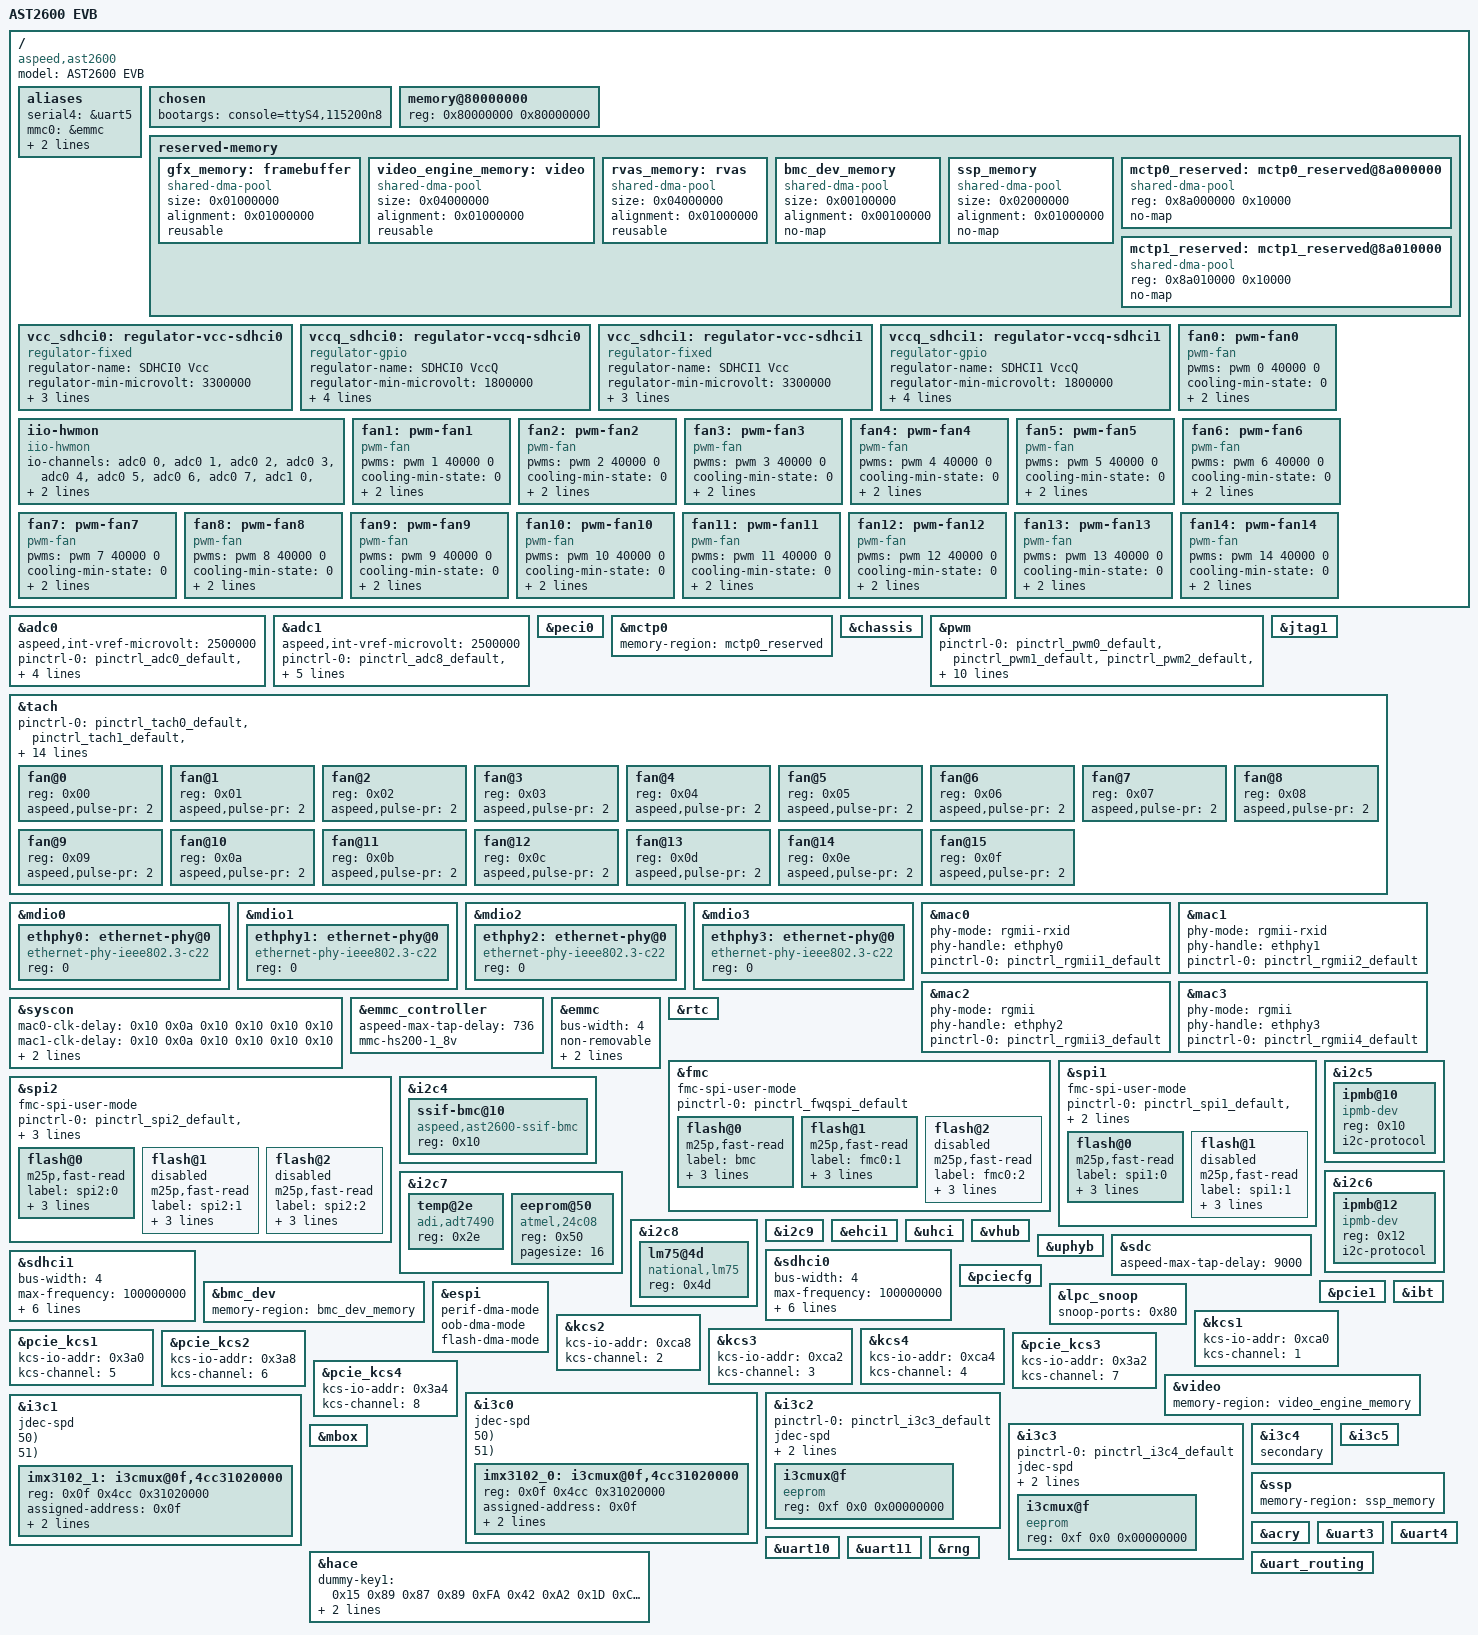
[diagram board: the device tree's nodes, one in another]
// SPDX-License-Identifier: GPL-2.0-or-later
// Copyright 2019 IBM Corp.

/dts-v1/;

#include "aspeed-g6.dtsi"
#include <dt-bindings/gpio/aspeed-gpio.h>

/ {
	model = "AST2600 EVB";
	compatible = "aspeed,ast2600";

	aliases {
		serial4 = &uart5;
		mmc0 = &emmc;
		mmc1 = &sdhci0;
		mmc2 = &sdhci1;
	};

	chosen {
		bootargs = "console=ttyS4,115200n8";
	};

	memory@80000000 {
		device_type = "memory";
		reg = <0x80000000 0x80000000>;
	};

	reserved-memory {
		#address-cells = <1>;
		#size-cells = <1>;
		ranges;

		gfx_memory: framebuffer {
			size = <0x01000000>;
			alignment = <0x01000000>;
			compatible = "shared-dma-pool";
			reusable;
		};

		video_engine_memory: video {
			size = <0x04000000>;
			alignment = <0x01000000>;
			compatible = "shared-dma-pool";
			reusable;
		};

		rvas_memory: rvas {
			size = <0x04000000>;
			alignment = <0x01000000>;
			compatible = "shared-dma-pool";
			reusable;
		};

		bmc_dev_memory: bmc_dev_memory {
			size = <0x00100000>;
			alignment = <0x00100000>;
			compatible = "shared-dma-pool";
			no-map;
		};

		ssp_memory: ssp_memory {
			size = <0x02000000>;
			alignment = <0x01000000>;
			compatible = "shared-dma-pool";
			no-map;
		};

		mctp0_reserved: mctp0_reserved@8a000000 {
			reg = <0x8a000000 0x10000>;
			compatible = "shared-dma-pool";
			no-map;
		};

		mctp1_reserved: mctp1_reserved@8a010000 {
			reg = <0x8a010000 0x10000>;
			compatible = "shared-dma-pool";
			no-map;
		};
	};

	vcc_sdhci0: regulator-vcc-sdhci0 {
		compatible = "regulator-fixed";
		regulator-name = "SDHCI0 Vcc";
		regulator-min-microvolt = <3300000>;
		regulator-max-microvolt = <3300000>;
		gpios = <&gpio0 ASPEED_GPIO(V, 0) GPIO_ACTIVE_HIGH>;
		enable-active-high;
	};

	vccq_sdhci0: regulator-vccq-sdhci0 {
		compatible = "regulator-gpio";
		regulator-name = "SDHCI0 VccQ";
		regulator-min-microvolt = <1800000>;
		regulator-max-microvolt = <3300000>;
		gpios = <&gpio0 ASPEED_GPIO(V, 1) GPIO_ACTIVE_HIGH>;
		gpios-states = <1>;
		states = <3300000 1>,
			 <1800000 0>;
	};

	vcc_sdhci1: regulator-vcc-sdhci1 {
		compatible = "regulator-fixed";
		regulator-name = "SDHCI1 Vcc";
		regulator-min-microvolt = <3300000>;
		regulator-max-microvolt = <3300000>;
		gpios = <&gpio0 ASPEED_GPIO(V, 2) GPIO_ACTIVE_HIGH>;
		enable-active-high;
	};

	vccq_sdhci1: regulator-vccq-sdhci1 {
		compatible = "regulator-gpio";
		regulator-name = "SDHCI1 VccQ";
		regulator-min-microvolt = <1800000>;
		regulator-max-microvolt = <3300000>;
		gpios = <&gpio0 ASPEED_GPIO(V, 3) GPIO_ACTIVE_HIGH>;
		gpios-states = <1>;
		states = <3300000 1>,
			 <1800000 0>;
	};
	iio-hwmon {
		compatible = "iio-hwmon";
		io-channels = <&adc0 0>, <&adc0 1>, <&adc0 2>, <&adc0 3>,
				<&adc0 4>, <&adc0 5>, <&adc0 6>, <&adc0 7>,
				<&adc1 0>, <&adc1 1>, <&adc1 2>, <&adc1 3>,
				<&adc1 4>, <&adc1 5>, <&adc1 6>, <&adc1 7>;
	};

	fan0: pwm-fan0 {
		compatible = "pwm-fan";
		pwms = <&pwm 0 40000 0>;	/* Target freq:25 kHz */
		cooling-min-state = <0>;
		cooling-max-state = <3>;
		#cooling-cells = <2>;
		cooling-levels = <0 15 128 255>;
	};

	fan1: pwm-fan1 {
		compatible = "pwm-fan";
		pwms = <&pwm 1 40000 0>;	/* Target freq:25 kHz */
		cooling-min-state = <0>;
		cooling-max-state = <3>;
		#cooling-cells = <2>;
		cooling-levels = <0 15 128 255>;
	};

	fan2: pwm-fan2 {
		compatible = "pwm-fan";
		pwms = <&pwm 2 40000 0>;	/* Target freq:25 kHz */
		cooling-min-state = <0>;
		cooling-max-state = <3>;
		#cooling-cells = <2>;
		cooling-levels = <0 15 128 255>;
	};

	fan3: pwm-fan3 {
		compatible = "pwm-fan";
		pwms = <&pwm 3 40000 0>;	/* Target freq:25 kHz */
		cooling-min-state = <0>;
		cooling-max-state = <3>;
		#cooling-cells = <2>;
		cooling-levels = <0 15 128 255>;
	};

	fan4: pwm-fan4 {
		compatible = "pwm-fan";
		pwms = <&pwm 4 40000 0>;	/* Target freq:25 kHz */
		cooling-min-state = <0>;
		cooling-max-state = <3>;
		#cooling-cells = <2>;
		cooling-levels = <0 15 128 255>;
	};

	fan5: pwm-fan5 {
		compatible = "pwm-fan";
		pwms = <&pwm 5 40000 0>;	/* Target freq:25 kHz */
		cooling-min-state = <0>;
		cooling-max-state = <3>;
		#cooling-cells = <2>;
		cooling-levels = <0 15 128 255>;
	};

	fan6: pwm-fan6 {
		compatible = "pwm-fan";
		pwms = <&pwm 6 40000 0>;	/* Target freq:25 kHz */
		cooling-min-state = <0>;
		cooling-max-state = <3>;
		#cooling-cells = <2>;
		cooling-levels = <0 15 128 255>;
	};

	fan7: pwm-fan7 {
		compatible = "pwm-fan";
		pwms = <&pwm 7 40000 0>;	/* Target freq:25 kHz */
		cooling-min-state = <0>;
		cooling-max-state = <3>;
		#cooling-cells = <2>;
		cooling-levels = <0 15 128 255>;
	};

	fan8: pwm-fan8 {
		compatible = "pwm-fan";
		pwms = <&pwm 8 40000 0>;	/* Target freq:25 kHz */
		cooling-min-state = <0>;
		cooling-max-state = <3>;
		#cooling-cells = <2>;
		cooling-levels = <0 15 128 255>;
	};

	fan9: pwm-fan9 {
		compatible = "pwm-fan";
		pwms = <&pwm 9 40000 0>;	/* Target freq:25 kHz */
		cooling-min-state = <0>;
		cooling-max-state = <3>;
		#cooling-cells = <2>;
		cooling-levels = <0 15 128 255>;
	};

	fan10: pwm-fan10 {
		compatible = "pwm-fan";
		pwms = <&pwm 10 40000 0>;	/* Target freq:25 kHz */
		cooling-min-state = <0>;
		cooling-max-state = <3>;
		#cooling-cells = <2>;
		cooling-levels = <0 15 128 255>;
	};

	fan11: pwm-fan11 {
		compatible = "pwm-fan";
		pwms = <&pwm 11 40000 0>;	/* Target freq:25 kHz */
		cooling-min-state = <0>;
		cooling-max-state = <3>;
		#cooling-cells = <2>;
		cooling-levels = <0 15 128 255>;
	};

	fan12: pwm-fan12 {
		compatible = "pwm-fan";
		pwms = <&pwm 12 40000 0>;	/* Target freq:25 kHz */
		cooling-min-state = <0>;
		cooling-max-state = <3>;
		#cooling-cells = <2>;
		cooling-levels = <0 15 128 255>;
	};

	fan13: pwm-fan13 {
		compatible = "pwm-fan";
		pwms = <&pwm 13 40000 0>;	/* Target freq:25 kHz */
		cooling-min-state = <0>;
		cooling-max-state = <3>;
		#cooling-cells = <2>;
		cooling-levels = <0 15 128 255>;
	};

	fan14: pwm-fan14 {
		compatible = "pwm-fan";
		pwms = <&pwm 14 40000 0>;	/* Target freq:25 kHz */
		cooling-min-state = <0>;
		cooling-max-state = <3>;
		#cooling-cells = <2>;
		cooling-levels = <0 15 128 255>;
	};
};

&adc0 {
	aspeed,int-vref-microvolt = <2500000>;
	status = "okay";

	pinctrl-names = "default";
	pinctrl-0 = <&pinctrl_adc0_default &pinctrl_adc1_default
		&pinctrl_adc2_default &pinctrl_adc3_default
		&pinctrl_adc4_default &pinctrl_adc5_default
		&pinctrl_adc6_default &pinctrl_adc7_default>;
};

&adc1 {
	aspeed,int-vref-microvolt = <2500000>;
	status = "okay";

	pinctrl-names = "default";
	pinctrl-0 = <&pinctrl_adc8_default &pinctrl_adc9_default
		&pinctrl_adc10_default &pinctrl_adc11_default
		&pinctrl_adc12_default &pinctrl_adc13_default
		&pinctrl_adc14_default &pinctrl_adc15_default>;
};

&peci0 {
	status = "okay";
};

&mctp0 {
	status = "okay";
	memory-region = <&mctp0_reserved>;
};

&chassis {
	status = "okay";
};

&pwm {
	status = "okay";
	pinctrl-names = "default";
	pinctrl-0 = <&pinctrl_pwm0_default
			&pinctrl_pwm1_default
			&pinctrl_pwm2_default
			&pinctrl_pwm3_default
			&pinctrl_pwm4_default
			&pinctrl_pwm5_default
			&pinctrl_pwm6_default
			&pinctrl_pwm7_default
			&pinctrl_pwm8g1_default
			&pinctrl_pwm9g1_default
			&pinctrl_pwm10g1_default
			&pinctrl_pwm11g1_default
			&pinctrl_pwm12g1_default
			&pinctrl_pwm13g1_default
			&pinctrl_pwm14g1_default>;
};

&jtag1 {
	status = "okay";
};

&tach {
	status = "okay";
	pinctrl-names = "default";
	pinctrl-0 = <&pinctrl_tach0_default
			&pinctrl_tach1_default
			&pinctrl_tach2_default
			&pinctrl_tach3_default
			&pinctrl_tach4_default
			&pinctrl_tach5_default
			&pinctrl_tach6_default
			&pinctrl_tach7_default
			&pinctrl_tach8_default
			&pinctrl_tach9_default
			&pinctrl_tach10_default
			&pinctrl_tach11_default
			&pinctrl_tach12_default
			&pinctrl_tach13_default
			&pinctrl_tach14_default
			&pinctrl_tach15_default>;
	fan@0 {
		reg = <0x00>;
		aspeed,pulse-pr = <2>;
	};

	fan@1 {
		reg = <0x01>;
		aspeed,pulse-pr = <2>;
	};

	fan@2 {
		reg = <0x02>;
		aspeed,pulse-pr = <2>;
	};

	fan@3 {
		reg = <0x03>;
		aspeed,pulse-pr = <2>;
	};

	fan@4 {
		reg = <0x04>;
		aspeed,pulse-pr = <2>;
	};

	fan@5 {
		reg = <0x05>;
		aspeed,pulse-pr = <2>;
	};

	fan@6 {
		reg = <0x06>;
		aspeed,pulse-pr = <2>;
	};

	fan@7 {
		reg = <0x07>;
		aspeed,pulse-pr = <2>;
	};

	fan@8 {
		reg = <0x08>;
		aspeed,pulse-pr = <2>;
	};

	fan@9 {
		reg = <0x09>;
		aspeed,pulse-pr = <2>;
	};

	fan@10 {
		reg = <0x0a>;
		aspeed,pulse-pr = <2>;
	};

	fan@11 {
		reg = <0x0b>;
		aspeed,pulse-pr = <2>;
	};

	fan@12 {
		reg = <0x0c>;
		aspeed,pulse-pr = <2>;
	};

	fan@13 {
		reg = <0x0d>;
		aspeed,pulse-pr = <2>;
	};

	fan@14 {
		reg = <0x0e>;
		aspeed,pulse-pr = <2>;
	};

	fan@15 {
		reg = <0x0f>;
		aspeed,pulse-pr = <2>;
	};
};

&mdio0 {
	status = "okay";

	ethphy0: ethernet-phy@0 {
		compatible = "ethernet-phy-ieee802.3-c22";
		reg = <0>;
	};
};

&mdio1 {
	status = "okay";

	ethphy1: ethernet-phy@0 {
		compatible = "ethernet-phy-ieee802.3-c22";
		reg = <0>;
	};
};

&mdio2 {
	status = "okay";

	ethphy2: ethernet-phy@0 {
		compatible = "ethernet-phy-ieee802.3-c22";
		reg = <0>;
	};
};

&mdio3 {
	status = "okay";

	ethphy3: ethernet-phy@0 {
		compatible = "ethernet-phy-ieee802.3-c22";
		reg = <0>;
	};
};

&mac0 {
	status = "okay";

	phy-mode = "rgmii-rxid";
	phy-handle = <&ethphy0>;

	pinctrl-names = "default";
	pinctrl-0 = <&pinctrl_rgmii1_default>;
};

&mac1 {
	status = "okay";

	phy-mode = "rgmii-rxid";
	phy-handle = <&ethphy1>;

	pinctrl-names = "default";
	pinctrl-0 = <&pinctrl_rgmii2_default>;
};

&mac2 {
	status = "okay";

	phy-mode = "rgmii";
	phy-handle = <&ethphy2>;

	pinctrl-names = "default";
	pinctrl-0 = <&pinctrl_rgmii3_default>;
};

&mac3 {
	status = "okay";

	phy-mode = "rgmii";
	phy-handle = <&ethphy3>;

	pinctrl-names = "default";
	pinctrl-0 = <&pinctrl_rgmii4_default>;
};

&syscon {
	mac0-clk-delay = <0x10 0x0a
			  0x10 0x10
			  0x10 0x10>;
	mac1-clk-delay = <0x10 0x0a
			  0x10 0x10
			  0x10 0x10>;
	mac2-clk-delay = <0x08 0x04
			  0x08 0x04
			  0x08 0x04>;
	mac3-clk-delay = <0x08 0x04
			  0x08 0x04
			  0x08 0x04>;
};

&emmc_controller {
	status = "okay";
	aspeed-max-tap-delay = <736>;
	mmc-hs200-1_8v;
};

&emmc {
	status = "okay";
#if 1
	bus-width = <4>;
#else
	bus-width = <8>;
	pinctrl-0 = <&pinctrl_emmc_default
			&pinctrl_emmcg8_default>;
#endif
	non-removable;
	max-frequency = <100000000>;
	/* <0 (MHz * 0.26496)>, <1 (MHz * 0.04968 + 180)> */
	clk-phase-mmc-hs200 = <0 27>, <1 185>;
	/*
	 * max-frequency = <200000000>;
	 * clk-phase-mmc-hs200 = <0 53>, <1 190>;
	 */
};

&rtc {
	status = "okay";
};

&fmc {
	fmc-spi-user-mode;
	pinctrl-names = "default";
	pinctrl-0 = <&pinctrl_fwqspi_default>;
	status = "okay";

	flash@0 {
		status = "okay";
		m25p,fast-read;
		label = "bmc";
		spi-max-frequency = <50000000>;
		spi-tx-bus-width = <4>;
		spi-rx-bus-width = <4>;
#include "aspeed-evb-flash-layout-64.dtsi"
	};

	flash@1 {
		status = "okay";
		m25p,fast-read;
		label = "fmc0:1";
		spi-max-frequency = <50000000>;
		spi-tx-bus-width = <4>;
		spi-rx-bus-width = <4>;
	};

	flash@2 {
		status = "disabled";
		m25p,fast-read;
		label = "fmc0:2";
		spi-max-frequency = <50000000>;
		spi-tx-bus-width = <4>;
		spi-rx-bus-width = <4>;
	};
};

&spi1 {
	fmc-spi-user-mode;
	pinctrl-names = "default";
	pinctrl-0 = <&pinctrl_spi1_default &pinctrl_spi1cs1_default
				&pinctrl_qspi1_default>;
	status = "okay";

	flash@0 {
		status = "okay";
		m25p,fast-read;
		label = "spi1:0";
		spi-max-frequency = <50000000>;
		spi-tx-bus-width = <4>;
		spi-rx-bus-width = <4>;
	};

	flash@1 {
		status = "disabled";
		m25p,fast-read;
		label = "spi1:1";
		spi-max-frequency = <50000000>;
		spi-tx-bus-width = <4>;
		spi-rx-bus-width = <4>;
	};
};

&spi2 {
	fmc-spi-user-mode;
	pinctrl-names = "default";
	pinctrl-0 = <&pinctrl_spi2_default &pinctrl_spi2cs1_default
				&pinctrl_spi2cs2_default &pinctrl_qspi2_default>;
	status = "okay";

	flash@0 {
		status = "okay";
		m25p,fast-read;
		label = "spi2:0";
		spi-max-frequency = <50000000>;
		spi-tx-bus-width = <4>;
		spi-rx-bus-width = <4>;
	};

	flash@1 {
		status = "disabled";
		m25p,fast-read;
		label = "spi2:1";
		spi-max-frequency = <50000000>;
		spi-tx-bus-width = <4>;
		spi-rx-bus-width = <4>;
	};

	flash@2 {
		status = "disabled";
		m25p,fast-read;
		label = "spi2:2";
		spi-max-frequency = <50000000>;
		spi-tx-bus-width = <4>;
		spi-rx-bus-width = <4>;
	};

};

&i2c4 {
	status = "okay";

	ssif-bmc@10 {
		compatible = "aspeed,ast2600-ssif-bmc";
		reg = <0x10>;
	};
};

&i2c5 {
	status = "okay";

	ipmb@10 {
		compatible = "ipmb-dev";
		reg = <0x10>;
		i2c-protocol;
	};
};

&i2c6 {
	status = "okay";

	ipmb@12 {
		compatible = "ipmb-dev";
		reg = <0x12>;
		i2c-protocol;
	};
};

&i2c7 {
	status = "okay";

	temp@2e {
		compatible = "adi,adt7490";
		reg = <0x2e>;
	};

	eeprom@50 {
		compatible = "atmel,24c08";
		reg = <0x50>;
		pagesize = <16>;
	};

};

&i2c8 {
	status = "okay";

	lm75@4d {
		compatible = "national,lm75";
		reg = <0x4d>;
	};

};

&i2c9 {
	status = "okay";
};

#if 0
&ehci0 {
	status = "okay";
};
#endif

&ehci1 {
	status = "okay";
};

&uhci {
	status = "okay";
};

&vhub {
	status = "okay";
	pinctrl-names = "default";
#if 0
	pinctrl-0 = <&pinctrl_usb2adp_default>;
#endif
};

#if 0
&udc {
	status = "okay";
	pinctrl-names = "default";
	pinctrl-0 = <&pinctrl_usb2bd_default>;
};
#endif

&uphyb {
	status = "okay";
};

#if 0
&gfx {
	pcie-reset-detect;
	status = "okay";
	memory-region = <&gfx_memory>;
};
#endif

&sdc {
	status = "okay";
	aspeed-max-tap-delay = <9000>;
};

/*
 * The signal voltage of sdhci0 and sdhci1 on AST2600-A2 EVB is able to be
 * toggled by GPIO pins.
 * In the reference design, GPIOV0 of AST2600-A2 EVB is connected to the
 * power load switch that provides 3.3v to sdhci0 vdd, GPIOV1 is connected to
 * a 1.8v and a 3.3v power load switch that provides signal voltage to
 * sdhci0 bus.
 * If GPIOV0 is active high, sdhci0 is enabled, otherwise, sdhci0 is disabled.
 * If GPIOV1 is active high, 3.3v power load switch is enabled, sdhci0 signal
 * voltage is 3.3v, otherwise, 1.8v power load switch will be enabled,
 * sdhci0 signal voltage becomes 1.8v.
 * AST2600-A2 EVB also supports toggling signal voltage for sdhci1.
 * The design is the same as sdhci0, it uses GPIOV2 as power-gpio and GPIOV3
 * as power-switch-gpio.
 */
&sdhci0 {
	status = "okay";
	bus-width = <4>;
	max-frequency = <100000000>;
	sdhci-drive-type = /bits/ 8 <3>;
	/* SDR104/DDR50 bits in CAPA2 are not supported */
	sdhci-caps-mask = <0x6 0x0>;
	sdhci,wp-inverted;
	vmmc-supply = <&vcc_sdhci0>;
	vqmmc-supply = <&vccq_sdhci0>;
	/* <0 (MHz * 1.296)>, <1 (MHz * 2.376)> */
	clk-phase-uhs-sdr50 = <0 130>, <0 238>;
};

&sdhci1 {
	status = "okay";
	bus-width = <4>;
	max-frequency = <100000000>;
	sdhci-drive-type = /bits/ 8 <3>;
	/* SDR104/DDR50 bits in CAPA2 are not supported */
	sdhci-caps-mask = <0x6 0x0>;
	sdhci,wp-inverted;
	vmmc-supply = <&vcc_sdhci1>;
	vqmmc-supply = <&vccq_sdhci1>;
	/* <0 (MHz * 1.296)>, <1 (MHz * 1.296)> */
	clk-phase-uhs-sdr50 = <0 130>, <0 130>;
};

&bmc_dev {
	status = "okay";
	memory-region = <&bmc_dev_memory>;
};

&pciecfg {
	status = "okay";
};

&pcie1 {
	status = "okay";
};

&espi {
	status = "okay";
	perif-dma-mode;
	oob-dma-mode;
	flash-dma-mode;
};

&lpc_snoop {
	status = "okay";
	snoop-ports = <0x80>;
};

&ibt {
	status = "okay";
};

&kcs1 {
	kcs-io-addr = <0xca0>;
	kcs-channel = <1>;
	status = "okay";
};

&kcs2 {
	kcs-io-addr = <0xca8>;
	kcs-channel = <2>;
	status = "okay";
};

&kcs3 {
	kcs-io-addr = <0xca2>;
	kcs-channel = <3>;
	status = "okay";
};

&kcs4 {
	kcs-io-addr = <0xca4>;
	kcs-channel = <4>;
	status = "okay";
};

&pcie_kcs1 {
	kcs-io-addr = <0x3a0>;
	kcs-channel = <5>;
	status = "okay";
};

&pcie_kcs2 {
	kcs-io-addr = <0x3a8>;
	kcs-channel = <6>;
	status = "okay";
};

&pcie_kcs3 {
	kcs-io-addr = <0x3a2>;
	kcs-channel = <7>;
	status = "okay";
};

&pcie_kcs4 {
	kcs-io-addr = <0x3a4>;
	kcs-channel = <8>;
	status = "okay";
};

#if 1
&video {
	status = "okay";
	memory-region = <&video_engine_memory>;
};
#else
&rvas {
	status = "okay";
	memory-region = <&rvas_memory>;
};
#endif

/*
 * Aspeed I3C daughter card configuration
 *
 * IMX3102: 2-to-1 multiplexier
 * SPD5118: SPD Hub device
 *
 * +---------------------+
 * | SoC                 |
 * |                     |
 * | I3C controller #0 - | --+
 * |                     |    \                 SPD5118@50 (I3C mode)
 * |                     |     +-----------+    |
 * |                     |     | IMX3102@f | ---+--+---- i3c bus
 * |                     |     | (I3C mode)|       |
 * |                     |     +-----------+       |
 * |                     |    /                    SPD5118@51 (I3C mode)
 * | I3C controller #1 - | --+
 * |                     |
 * |                     |
 * | I3C controller #2 - | --+
 * |                     |    \                 SPD5118@52 (I2C mode)
 * |                     |     +-----------+    |
 * |                     |     | IMX3102@f | ---+--+---- i2c bus
 * |                     |     | (I2C mode)|       |
 * |                     |     +-----------+       |
 * |                     |    /                    SPD5118@53 (I2C mode)
 * | I3C controller #3 - | --+
 * |                     |
 * +---------------------+
 */
#define JESD300_SPD_I2C_MODE(bus, index, addr) \
spd_ ## bus ## _ ## index: spd@addr { \
	compatible = "eeprom"; \
	reg = <0x ## addr 0x0 0x0>; \
}

#define JESD300_SPD_I3C_MODE(bus, index, addr) \
spd_ ## bus ## _ ## index: spd@addr,4cc5118 ## index ## 000 { \
	reg = <0x ## addr 0x4cc 0x5118 ## index ## 000>; \
	assigned-address = <0x ## addr>; \
	dcr = <0xda>; \
	bcr = <0x6>; \
}

&i3c0 {
	status = "okay";
	jdec-spd;
	/* Renesas IMX3102 multiplexer w/ thermal sensor */
	imx3102_0: i3cmux@0f,4cc31020000 {
		reg = <0x0f 0x4cc 0x31020000>;
		assigned-address = <0x0f>;
		dcr = <0xd1>;
		bcr = <0x6>;
	};

	JESD300_SPD_I3C_MODE(0, 0, 50);
	JESD300_SPD_I3C_MODE(0, 1, 51);
};

&i3c1 {
	status = "okay";
	jdec-spd;
	/* Renesas IMX3102 multiplexer w/ thermal sensor */
	imx3102_1: i3cmux@0f,4cc31020000 {
		reg = <0x0f 0x4cc 0x31020000>;
		assigned-address = <0x0f>;
		dcr = <0xd1>;
		bcr = <0x6>;
	};

	JESD300_SPD_I3C_MODE(1, 0, 50);
	JESD300_SPD_I3C_MODE(1, 1, 51);
};

&i3c2 {
	status = "okay";
	pinctrl-names = "default";
	pinctrl-0 = <&pinctrl_i3c3_default>;

	jdec-spd;
	/* Renesas IMX3102 multiplexer w/ thermal sensor */
	i3cmux@f {
		compatible = "eeprom";
		reg = <0xf 0x0 0x00000000>;
	};

	JESD300_SPD_I2C_MODE(2, 0, 52);
	JESD300_SPD_I2C_MODE(2, 1, 53);
};

&i3c3 {
	status = "okay";
	pinctrl-names = "default";
	pinctrl-0 = <&pinctrl_i3c4_default>;

	jdec-spd;
	/* Renesas IMX3102 multiplexer w/ thermal sensor */
	i3cmux@f {
		compatible = "eeprom";
		reg = <0xf 0x0 0x00000000>;
	};

	JESD300_SPD_I2C_MODE(3, 0, 52);
	JESD300_SPD_I2C_MODE(3, 1, 53);
};

/*
 * I3C loopback: connect I3C4 (slave) to I3C5 (master)
 * Three devices will be created under /sys/bus/i3c/devices
 *   i3c-4: represent i3c4 controller, play the role as the slave device
 *   i3c-5: represent i3c5 controller, play the role as the master device
 *   5-7ec05034000: represent the slave device attached to the bus hosted by
 *                  i3c-5 controller.  In this case, 5-7ec05034000 maps to the
 *                  physical device i3c4.
 */
&i3c4 {
	status = "okay";
	secondary;
};

&i3c5 {
	status = "okay";
};

&ssp {
	memory-region = <&ssp_memory>;
};

&mbox {
	status = "okay";
};

&hace {
	status = "okay";
	dummy-key1 = /bits/ 8 <0x15 0x89 0x87 0x89 0xFA 0x42 0xA2 0x1D 0xCE 0x85 0x78 0x1A 0x39 0xFA 0xD7 0x5B 0xFD 0x65 0x32 0xC5 0x25 0x6B 0x34 0xCC 0xEE 0x70 0x03 0x23 0x29 0x06 0x57 0xD0>;
	dummy-key2 = /bits/ 8 <0x02 0x89 0x87 0x89 0xFA 0x42 0xA2 0x1D 0xCE 0x85 0x78 0x1A 0x39 0xFA 0xD7 0x5B 0xFD 0x65 0x32 0xC5 0x25 0x6B 0x34 0xCC 0xEE 0x70 0x03 0x23 0x29 0x06 0x57 0xD0>;
};

&acry {
	status = "okay";
};

&uart3 {
	status = "okay";
};

&uart4 {
	status = "okay";
};

&uart10 {
	status = "okay";
};

&uart11 {
	status = "okay";
};

&uart_routing {
	status = "okay";
};

&rng {
	status = "okay";
};
